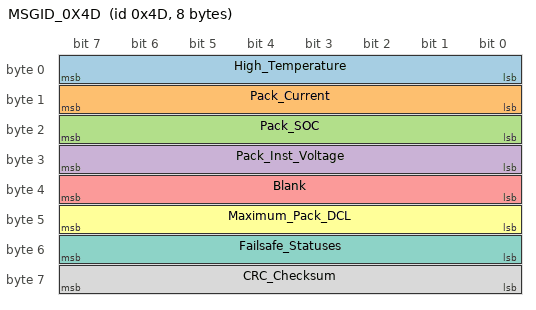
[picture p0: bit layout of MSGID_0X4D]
BO_ 77 MSGID_0X4D: 8 BMS
 SG_ High_Temperature : 7|8@0+ (1.0,0) [0|0] "Celsius"  Third_Party_Device
 SG_ Pack_Current : 15|8@0+ (0.1,0) [0|0] "Amps"  Third_Party_Device
 SG_ Pack_SOC : 23|8@0+ (0.5,0) [0|0] "Percent"  Third_Party_Device
 SG_ Pack_Inst_Voltage : 31|8@0+ (0.1,0) [0|0] "Volts"  Third_Party_Device
 SG_ Blank : 39|8@0+ (1.0,0) [0|0] ""  Third_Party_Device
 SG_ Maximum_Pack_DCL : 47|8@0+ (1.0,0) [0|0] "Amps"  Third_Party_Device
 SG_ Failsafe_Statuses : 55|8@0+ (1.0,0) [0|0] ""  Third_Party_Device
 SG_ CRC_Checksum : 63|8@0+ (1.0,0) [0|0] ""  Third_Party_Device

 BA_ "MoTeC_Channel" SG_ 77 High_Temperature "High Temperature";
 BA_ "MoTeC_Channel" SG_ 77 Pack_Current "Pack Current";
 BA_ "MoTeC_Channel" SG_ 77 Pack_SOC "Pack State of Charge";
 BA_ "MoTeC_Channel" SG_ 77 Pack_Inst_Voltage "Pack Instant Voltage";
 BA_ "MoTeC_Channel" SG_ 77 Maximum_Pack_DCL "Maximum Pack DCL";
